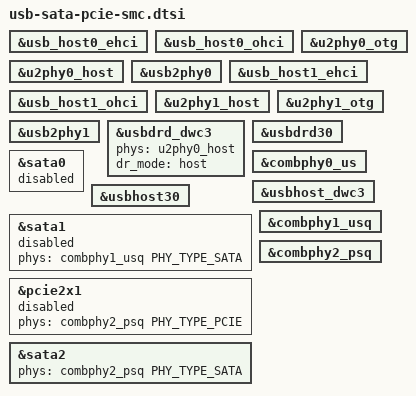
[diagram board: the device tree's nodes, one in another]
/*
	USB2_HOST2
*/

/*
	This controller is connected to USB1 pins on SMARC connector
*/
&usb_host0_ehci {
	status = "okay";
};

/*
	This controller is connected to USB1 pins on SMARC connector
*/
&usb_host0_ohci {
	status = "okay";
};

&u2phy0_host {
	status = "okay";
};

&u2phy0_otg {
	status = "okay";
};

&usb2phy0 {
	status = "okay";
};

/*
	USB2_HOST3
*/

/*
	This controller is connected to USB0 pins on SMARC connector
*/
&usb_host1_ehci {
	status = "okay";
};

/*
	This controller is connected to USB0 pins on SMARC connector
*/
&usb_host1_ohci {
	status = "okay";
};


&u2phy1_host {
	status = "okay";
};

&u2phy1_otg {
	status = "okay";
};

&usb2phy1 {
	status = "okay";
};

/*
	USB3_OTG0 or SATA0
*/

/*
	This controller is connected to USB3 pins on SMARC connector X1 (conga SMC1 lower X4)
*/
&usbdrd_dwc3 {
	phys = <&u2phy0_host>;
//	extcon = <&usb2phy0>;
	dr_mode = "host";
	// If this controller is enabled, sata0 must be disabled
	status = "okay";
};

&usbdrd30 {
	status = "okay";
};

&sata0 {
	// If this controller is enabled, usbdrd_dwc3 must be disabled
	status = "disabled";
};


// This controller is phy for usbdrd_dwc3 and sata0 controllers
&combphy0_us {
	status = "okay";
};

/*
	USB3_HOST1 or SATA1
*/

/*
	This controller is connected to USB2 pins on SMARC connector X1 (conga SMC1 upper X4)
*/
&usbhost_dwc3 {
	// If this controller is enabled, sata1 must be disabled
	status = "okay";
};

&usbhost30 {
	status = "okay";
};

// This board doesn't use this controller
&sata1 {
	phys = <&combphy1_usq PHY_TYPE_SATA>;
	phy-names = "sata-phy";

	// If this controller is enabled, usbhost_dwc3 must be disabled
	status = "disabled";
};

// This controller is phy for usbhost_dwc3 and sata1 controllers
&combphy1_usq {
	status = "okay";
};

/*
	PCIE2x1 or SATA2
*/

// This board doesn't use this controller
&pcie2x1 {
	phys = <&combphy2_psq PHY_TYPE_PCIE>;
	phy-names = "pcie-phy";
	status = "disabled";
};

/*
	SATA2 lines are connected to SATA pins on SMARC connector X1
*/
&sata2 {
    phys = <&combphy2_psq PHY_TYPE_SATA>;
    status = "okay";
};

// This controller is phy for pcie2x1 and sata2 controllers
&combphy2_psq {
	status = "okay";
};
